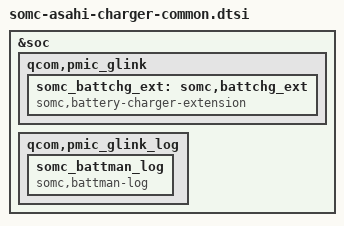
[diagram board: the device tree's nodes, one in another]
&soc {
	qcom,pmic_glink {
		somc_battchg_ext: somc,battchg_ext {
			compatible = "somc,battery-charger-extension";
		};
	};

	qcom,pmic_glink_log {
		somc_battman_log {
			compatible = "somc,battman-log";
		};
	};
};
